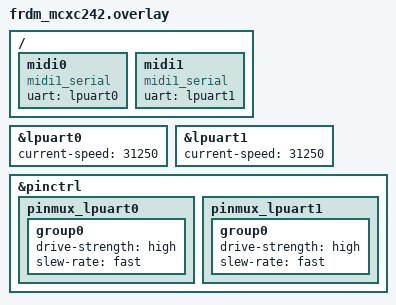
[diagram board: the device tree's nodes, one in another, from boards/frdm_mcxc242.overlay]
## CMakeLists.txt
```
cmake_minimum_required(VERSION 3.20.0)

set(DTS_ROOT ${CMAKE_CURRENT_SOURCE_DIR}/../..)

find_package(Zephyr REQUIRED HINTS $ENV{ZEPHYR_BASE})
project(midi1_parser_tests)

target_include_directories(app PRIVATE
    ${CMAKE_CURRENT_SOURCE_DIR}/../../src
    ${CMAKE_CURRENT_SOURCE_DIR}/../../drivers
)

target_sources(app PRIVATE
    ${CMAKE_CURRENT_SOURCE_DIR}/../../drivers/midi1_serial.c
    ${CMAKE_CURRENT_SOURCE_DIR}/../../src/note.c
    ${CMAKE_CURRENT_SOURCE_DIR}/src/test_midi1_parser.c
)
```

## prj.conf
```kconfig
# Enable ztest
CONFIG_ZTEST=y

# Enable thread safety for queues
CONFIG_MAIN_STACK_SIZE=2048

# Enable printk (your parser uses it when debug is on)
CONFIG_PRINTK=y

CONFIG_CONSOLE=n
CONFIG_UART_CONSOLE=n

# Enable minimal UART driver stubs (native_posix)
CONFIG_SERIAL=y

# For the qemu m0
#CONFIG_UART_NRFX=y
CONFIG_UART_INTERRUPT_DRIVEN=y

# Disable Zephyr banner for cleaner test output
CONFIG_BOOT_BANNER=n


CONFIG_SERIAL=y
CONFIG_SERIAL_INIT_PRIORITY=50
CONFIG_MIDI1_SERIAL=y
CONFIG_MIDI1_SERIAL_RUNNING_STATUS_REPEAT=16
CONFIG_MIDI1_SERIAL_RUNNING_STATUS_TIMEOUT_MS=300
CONFIG_MIDI1_SERIAL_ISR_MSGQ_SIZE_MS=128
```

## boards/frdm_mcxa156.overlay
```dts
/**
 * @file frdm_k64f.overlay
 * @brief overlay for this board from 2024
 * @note
 *
 * Using the MCXA156 the mikroBUS socket is used for lpuart1.
 *
 * @author Jan-Willem Smaal <usenet@gispen.org>
 * @date 20260102
 * SPDX-License-Identifier: Apache-2.0
 */

/*
 * Classic MIDI1.0 over DIN5 plug.
 * On the MCXA156 the mikroBUS socket J1 is on LPUART1
 */
&lpuart1 {
	status = "okay";
	/* Set it to the MIDI baud rate */
	current-speed = <31250>;
};

/ {
	midi0: midi0 {
                status = "okay";
                compatible = "midi1_serial";
                uart = <&lpuart1>;
        };	
};
```

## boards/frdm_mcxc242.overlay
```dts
/*
 * @brief FRDM-MCXW242 board configuration for the MIDI1.0 demo 
 * @note
 *
 * @author Jan-Willem Smaal
 * @date 20250101
 * SPDX-License-Identifier: Apache-2.0
 */
 
/*
 * Classic MIDI1.0 over DIN5 plug.
 * note on the FRDM-MCXC242 the LPUART0 is shared with the MCU_LINK.
 * so be aware!   If you send printk's you need to set the baud rate
 * to 31250 from the default 115200 to see something usefull
 *
 * Also note anything you send out to the MCU_LINK will end up on the MIDI
 * port!
 *
 */
&lpuart0 {
	status = "okay";
	/* Set it to the MIDI baud rate */
	current-speed = <31250>;
};

/* This one is on the MIKRObus and is not shared with the MCU_LINK. */
&lpuart1 {
	status = "okay";
	/* Set it to the MIDI baud rate */
	current-speed = <31250>;
};

&pinctrl {
	pinmux_lpuart0: pinmux_lpuart0 {
		group0 {
			/* Strongest drive + fast edges */
			drive-strength = "high";
			slew-rate = "fast";
		};
	};
	pinmux_lpuart1: pinmux_lpuart1 {
		group0 {
			/* Strongest drive + fast edges */
			drive-strength = "high";
			slew-rate = "fast";
		};
	};
};


/ {
	midi0: midi0 {
		status = "okay";
		compatible = "midi1_serial";
		uart = <&lpuart0>;
	};
	midi1: midi1 {
		status = "okay";
		compatible = "midi1_serial";
		uart = <&lpuart1>;
	};
};
```

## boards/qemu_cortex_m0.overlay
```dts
&uart0 {
        status = "okay";
        current-speed = <31250>;
};


/ {
	midi0: midi0 {
		status = "okay";
		compatible = "midi1_serial";
		uart = <&uart0>;
	};
};
```

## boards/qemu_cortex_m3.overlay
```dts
&uart1 {
        status = "okay";
        current-speed = <31250>;
};


/ {
	midi0: midi0 {
		status = "okay";
		compatible = "midi1_serial";
		uart = <&uart1>;
	};
};
```

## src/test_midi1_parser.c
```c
#include <zephyr/ztest.h>
#include <zephyr/device.h>
#include <zephyr/kernel.h>
#include <stdint.h>
#include "midi1.h"
#include "note.h"
#include "midi1_serial.h"

const struct device *midi = DEVICE_DT_GET(DT_NODELABEL(midi0));

/* Captured callback values */
static uint8_t cb_chan;
static uint8_t cb_note;
static uint8_t cb_vel;
static uint8_t cb_ctl;
static uint8_t cb_val;
static uint8_t cb_rt;
static uint8_t cb_prog;
static uint8_t cb_press;
static uint8_t cb_poly_note;
static uint8_t cb_poly_press;

static uint8_t sysex_buf[128];
static int sysex_len;

/* ---- Callback implementations ---- */

static void cb_note_on(uint8_t ch, uint8_t n, uint8_t v)
{
	cb_chan = ch;
	cb_note = n;
	cb_vel = v;
}

static void cb_note_off(uint8_t ch, uint8_t n, uint8_t v)
{
	cb_chan = ch;
	cb_note = n;
	cb_vel = v;
}

static void cb_control_change(uint8_t ch, uint8_t ctl, uint8_t val)
{
	cb_chan = ch;
	cb_ctl = ctl;
	cb_val = val;
}

static void cb_pitchwheel(uint8_t ch, uint8_t lsb, uint8_t msb)
{
	cb_chan = ch;
	cb_val = lsb;
	cb_vel = msb;
}

static void cb_program_change(uint8_t ch, uint8_t num)
{
	cb_chan = ch;
	cb_prog = num;
}

static void cb_channel_aftertouch(uint8_t ch, uint8_t pressure)
{
	cb_chan = ch;
	cb_press = pressure;
}

static void cb_poly_aftertouch(uint8_t ch, uint8_t note, uint8_t pressure)
{
	cb_chan = ch;
	cb_poly_note = note;
	cb_poly_press = pressure;
}

static void cb_realtime(uint8_t msg)
{
	cb_rt = msg;
}

static void cb_sysex_start(void)
{
	sysex_len = 0;
}

static void cb_sysex_data(uint8_t d)
{
	sysex_buf[sysex_len++] = d;
}

static void cb_sysex_stop(void)
{
}

/* ---- Helper: push one byte into msgq ---- */

static void push_byte(uint8_t b)
{
	struct midi1_serial_data *data = midi->data;
	k_msgq_put(&data->msgq, &b, K_NO_WAIT);
	midi1_serial_receiveparser(midi);
}

/* ---- TESTS ---- */

ZTEST(midi1_serial, test_note_on)
{
	push_byte(0x90);        /* status: note on ch0 */
	push_byte(60);          /* note */
	push_byte(100);         /* velocity */

	zassert_equal(cb_chan, 0, "wrong channel");
	zassert_equal(cb_note, 60, "wrong note");
	zassert_equal(cb_vel, 100, "wrong velocity");
}

ZTEST(midi1_serial, test_note_off_zero_velocity)
{
	push_byte(0x90);
	push_byte(60);
	push_byte(0);           /* velocity zero → note_off */

	zassert_equal(cb_note, 60, "wrong note");
	zassert_equal(cb_vel, 0, "wrong velocity");
}

ZTEST(midi1_serial, test_control_change)
{
	push_byte(0xB0);
	push_byte(7);           /* controller */
	push_byte(99);          /* value */

	zassert_equal(cb_ctl, 7, "wrong controller");
	zassert_equal(cb_val, 99, "wrong value");
}

ZTEST(midi1_serial, test_pitchwheel)
{
	push_byte(0xE0);
	push_byte(0x34);        /* LSB */
	push_byte(0x12);        /* MSB */

	zassert_equal(cb_val, 0x34, "wrong LSB");
	zassert_equal(cb_vel, 0x12, "wrong MSB");
}

ZTEST(midi1_serial, test_program_change)
{
	push_byte(0xC0);
	push_byte(42);

	zassert_equal(cb_prog, 42, "wrong program");
}

ZTEST(midi1_serial, test_poly_aftertouch)
{
	push_byte(0xA0);
	push_byte(60);
	push_byte(55);

	zassert_equal(cb_poly_note, 60, "wrong note");
	zassert_equal(cb_poly_press, 55, "wrong pressure");
}

ZTEST(midi1_serial, test_realtime)
{
	push_byte(0xF8);        /* timing clock */

	zassert_equal(cb_rt, 0xF8, "wrong realtime msg");
}

ZTEST(midi1_serial, test_sysex)
{
	push_byte(0xF0);        /* start */
	push_byte(0x01);
	push_byte(0x02);
	push_byte(0x03);
	push_byte(0xF7);        /* end */

	zassert_equal(sysex_len, 3, "wrong sysex length");
	zassert_equal(sysex_buf[0], 0x01, "wrong sysex byte 0");
	zassert_equal(sysex_buf[1], 0x02, "wrong sysex byte 1");
	zassert_equal(sysex_buf[2], 0x03, "wrong sysex byte 2");
}

ZTEST_SUITE(midi1_serial, NULL, NULL, NULL, NULL, NULL);

void test_main(void)
{
	zassert_true(device_is_ready(midi), "device not ready");

	struct midi1_serial_callbacks cb = {
		.note_on = cb_note_on,
		.note_off = cb_note_off,
		.control_change = cb_control_change,
		.pitchwheel = cb_pitchwheel,
		.program_change = cb_program_change,
		.channel_aftertouch = cb_channel_aftertouch,
		.poly_aftertouch = cb_poly_aftertouch,
		.realtime = cb_realtime,
		.sysex_start = cb_sysex_start,
		.sysex_data = cb_sysex_data,
		.sysex_stop = cb_sysex_stop,
	};

	zassert_ok(midi1_serial_register_callbacks(midi, &cb));
}
```
